# SA3_SS_SEC_PROXY_0_SEC_PROXY_44804000h register map
Vendor: Texas Instruments
Peripheral module from a debugger description file (folder AM275x).
Registers are 32-bit, read-only, reset 0x66367100 unless marked. A register's access mark holds for its fields unless they carry their own. Offsets are as the file gives them; lines under a group give offsets from that group; [hi:lo] are bit positions; {n}, {i} and the like mark numbered series; 'fields as' and 'values as' point back to an identical list; <NAME> marks a mode.

## sec_proxy
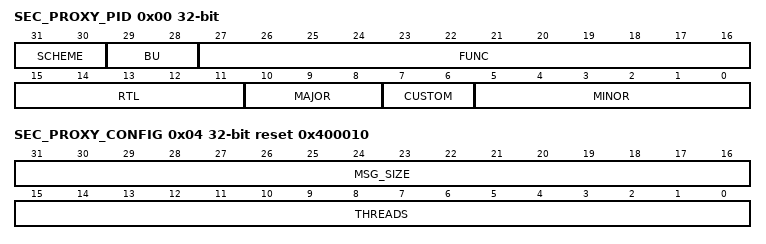
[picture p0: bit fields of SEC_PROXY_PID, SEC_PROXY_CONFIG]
0x00 SEC_PROXY_PID — The Revision Register contains the major and minor revisions for the module.
  [31:30] SCHEME — PID register scheme Reset Source: rst_mod_g_rst_n
  [29:28] BU — Business Unit: 10 = Processors Reset Source: rst_mod_g_rst_n
  [27:16] FUNC — Module ID Reset Source: rst_mod_g_rst_n
  [15:11] RTL — RTL revision. Will vary depending on release. Reset Source: rst_mod_g_rst_n
  [10:8] MAJOR — Major revision Reset Source: rst_mod_g_rst_n
  [7:6] CUSTOM — Custom Reset Source: rst_mod_g_rst_n
  [5:0] MINOR — Minor revision Reset Source: rst_mod_g_rst_n
0x04 SEC_PROXY_CONFIG reset 0x400010 — The Config Register shows configured params.
  [31:16] MSG_SIZE — Supported message size in bytes. Reset Source: rst_mod_g_rst_n
  [15:0] THREADS — Number of proxy threads supported. Reset Source: rst_mod_g_rst_n
0x14 SEC_PROXY_GLB_EVT rw reset 0xFFFF — The Global Event Register defines the event to send for a global error.
  [15:0] ERR_EVENT — Global error event destination. 0xFFFF disables the event Reset Source: rst_mod_g_rst_n
